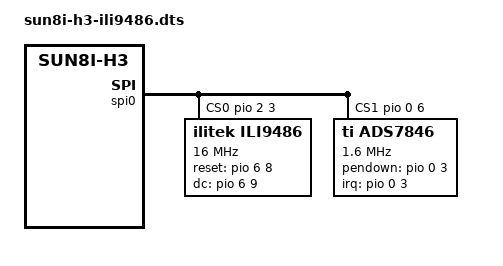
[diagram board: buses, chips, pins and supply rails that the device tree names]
/dts-v1/;
/plugin/;

/ {
    compatible = "allwinner,sun8i-h3";

    fragment@0 {
	target = <&spi0>;
	__overlay__ {
	    num-cs = <2>;
	    cs-gpios = <&pio 2 3 0>,
		       <&pio 0 6 0>;			
	    status = "okay";
	    #address-cells = <1>;
	    #size-cells = <0>;

	    ili9486: ili9486@0{
		compatible = "ilitek,ili9486";
		reg = <0>;
		spi-max-frequency = <16000000>;
		bgr;
		txbuflen = <32768>;
		fps = <30>;
		buswidth = <16>;
		regwidth = <16>;
		reset-gpios = <&pio 6 8 0>;
		dc-gpios = <&pio 6 9 0>;
		debug = <1>;

		init = <0x10000e0 0x00 0x07 0x0f 0x0d 0x1b 0x0a 0x3c 0x78 0x4a 0x07 0x0e 0x09 0x1b 0x1e 0x0f
			0x10000e1 0x00 0x22 0x24 0x06 0x12 0x07 0x36 0x47 0x47 0x06 0x0a 0x07 0x30 0x37 0x0f  
			0x10000c0 0x10 0x10 
			0x10000c1 0x41 
			0x10000c5 0x00 0x22 0x80 
			0x1000036 0x68 
			0x100003a 0x55 
			0x10000b0 0x00
			0x10000b1 0xb0 0x11
			0x10000b4 0x02
			0x10000b6 0x02 0x42
			0x10000b7 0xc6
			0x10000b7 0xc6
			0x10000f7 0xa9 0x51 0x2c 0x82
			0x1000011
			0x1000029>;
			
	    };

	    ads7846: ads7846@0 {
		compatible = "ti,ads7846";
		reg = <1>; 
		status = "okay";
		spi-max-frequency = <1600000>;
		interrupt-parent = <&pio>;
		interrupts = <0 3 2>; /* PA3 IRQ_TYPE_EDGE_FALLING */
		pendown-gpio = <&pio 0 3 0>; /* PA3 */

		/* driver defaults, optional */
		ti,x-min = /bits/ 16 <0>;
		ti,y-min = /bits/ 16 <0>;
		ti,x-max = /bits/ 16 <0x0FFF>;
		ti,y-max = /bits/ 16 <0x0FFF>;
		ti,pressure-min = /bits/ 16 <0>;
		ti,pressure-max = /bits/ 16 <0xFFFF>;
		ti,x-plate-ohms = /bits/ 16 <400>;
	};

	};
    };


};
